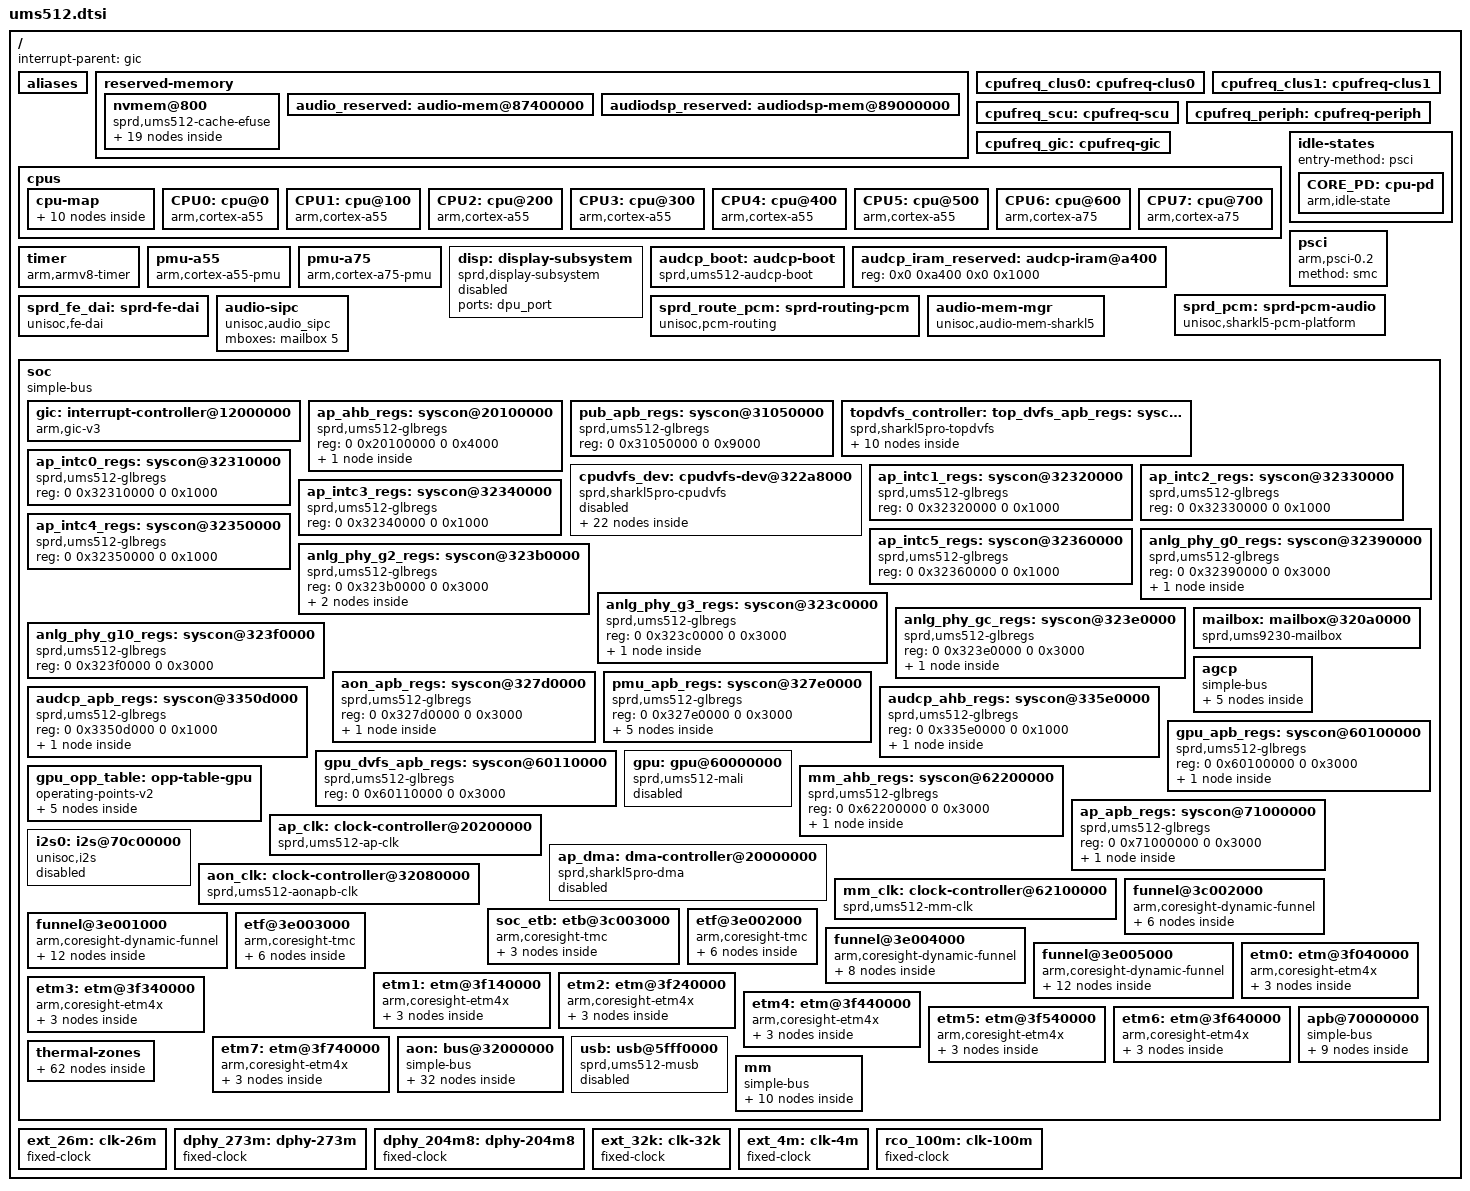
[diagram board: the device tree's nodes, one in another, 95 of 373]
// SPDX-License-Identifier: (GPL-2.0 OR MIT)
/*
 * Unisoc UMS512 SoC DTS file
 *
 * Copyright (C) 2021, Unisoc Inc.
 */

#include <dt-bindings/clock/sprd,ums512-clk.h>
#include <dt-bindings/reset/sprd,ums512-reset.h>
#include <dt-bindings/power/sprd,ums512-power.h>
#include <dt-bindings/interrupt-controller/arm-gic.h>
#include <dt-bindings/thermal/thermal.h>

/ {
	interrupt-parent = <&gic>;
	#address-cells = <2>;
	#size-cells = <2>;

	aliases {
		mmc0 = &sdio0;
		mmc3 = &sdio3;
		i2c0 = &i2c0;
		i2c1 = &i2c1;
		i2c2 = &i2c2;
		i2c3 = &i2c3;
		i2c4 = &i2c4;
	};

	reserved-memory {
		#address-cells = <2>;
		#size-cells = <2>;
		ranges;

		nvmem@800 {
			compatible = "sprd,ums512-cache-efuse", "nvmem-rmem";
			reg = <0 0x800 0 0x3ff>;
			no-map;

			nvmem-layout {
				compatible = "fixed-layout";
				#address-cells = <1>;
				#size-cells = <1>;

				thm0_sign: thm0-sign@38 {
					reg = <0x38 0x1>;
					bits = <0 1>;
				};

				thm0_ratio: thm0-ratio@38 {
					reg = <0x38 0x1>;
					bits = <1 7>;
				};

				thm0_sen0: thm0-sen0@39 {
					reg = <0x39 0x1>;
					bits = <0 8>;
				};

				thm0_sen1: thm0-sen1@41 {
					reg = <0x41 0x1>;
					bits = <0 8>;
				};

				thm0_sen2: thm0-sen2@40 {
					reg = <0x40 0x1>;
					bits = <0 8>;
				};

				thm0_sen3: thm0-sen3@43 {
					reg = <0x43 0x1>;
					bits = <0 8>;
				};

				thm0_sen4: thm0-sen4@42 {
					reg = <0x42 0x1>;
					bits = <0 8>;
				};

				thm1_sign: thm1-sign@3c {
					reg = <0x3c 0x1>;
					bits = <0 1>;
				};

				thm1_ratio: thm1-ratio@3c {
					reg = <0x3c 0x1>;
					bits = <1 7>;
				};

				thm1_sen0: thm1-sen0@3d {
					reg = <0x3d 0x1>;
					bits = <0 8>;
				};

				thm1_sen1: thm1-sen1@2f {
					reg = <0x2f 0x1>;
					bits = <0 8>;
				};

				thm1_sen2: thm1-sen2@2e {
					reg = <0x2e 0x1>;
					bits = <0 8>;
				};

				thm1_sen3: thm1-sen3@29 {
					reg = <0x29 0x1>;
					bits = <0 8>;
				};

				thm1_sen4: thm1-sen4@28 {
					reg = <0x28 0x1>;
					bits = <0 8>;
				};

				thm1_sen5: thm1-sen4@2b {
					reg = <0x2b 0x1>;
					bits = <0 8>;
				};

				thm2_sign: thm2-sign@3e {
					reg = <0x3e 0x1>;
					bits = <0 1>;
				};

				thm2_ratio: thm2-ratio@3e {
					reg = <0x3e 0x1>;
					bits = <1 7>;
				};

				thm2_sen0: thm2-sen0@3f {
					reg = <0x3f 0x1>;
					bits = <0 8>;
				};
			};
		};

		/* Stock audio carveouts (see device/stock/dtb_stock.dts) */
		audio_reserved: audio-mem@87400000 {
			reg = <0x0 0x87400000 0x0 0x400000>;
			no-map;
		};

		audiodsp_reserved: audiodsp-mem@89000000 {
			reg = <0x0 0x89000000 0x0 0x600000>;
			no-map;
		};
	};

	cpufreq_clus0: cpufreq-clus0 {
		cpufreq-cluster-id = <0>;
		cpufreq-sub-clusters = <&cpufreq_scu>,
				<&cpufreq_periph>,
				<&cpufreq_gic>;
		clock-latency = <50000>;
		voltage-tolerance = <6413>;
		sprd,multi-version;
		operating-points = <
		/* kHz     uV */
		1820000 1000000
		1716000 1000000
		1536000  900000
		1482000  900000
		1228800  800000
		1144000  800000
		962000   800000
		768000   800000
		614400   750000
		>;
	};

	cpufreq_clus1: cpufreq-clus1 {
		cpufreq-cluster-id = <1>;
		cpufreq-sub-clusters = <&cpufreq_scu>,
				<&cpufreq_periph>,
				<&cpufreq_gic>;
		clock-latency = <50000>;
		voltage-tolerance = <6413>;
		sprd,multi-version;
		operating-points = <
		/* kHz     uV */
		2002000 1000000
		1872000 1000000
		1742000 1000000
		1536000  900000
		1482000  800000
		1228800  750000
		>;
	};

	cpufreq_scu: cpufreq-scu {
		cpufreq-cluster-id = <2>;
		clock-latency = <50000>;
		voltage-tolerance = <0>;
		sprd,multi-version;
		operating-points = <
		/* kHz     uV */
		1404000 1000000
		1326000 1000000
		1222000  900000
		1118000  900000
		1014000  800000
		962000   800000
		768000   800000
		650000   800000
		546000   750000
		>;
	};

	cpufreq_periph: cpufreq-periph {
		cpufreq-cluster-id = <3>;
		clock-latency = <50000>;
		voltage-tolerance = <0>;
		sprd,multi-version;
		operating-points = <
		/* kHz    uV */
		768000 1000000
		512000  800000
		384000  800000
		256000  800000
		153600  750000
		>;
	};

	cpufreq_gic: cpufreq-gic {
		cpufreq-cluster-id = <4>;
		clock-latency = <50000>;
		voltage-tolerance = <0>;
		sprd,multi-version;
		operating-points = <
		/* kHz    uV */
		512000 800000
		384000 800000
		256000 800000
		192000 800000
		153600 750000
		>;
	};

	cpus {
		#address-cells = <2>;
		#size-cells = <0>;

		cpu-map {
			cluster0 {
				core0 {
					cpu = <&CPU0>;
				};
				core1 {
					cpu = <&CPU1>;
				};
				core2 {
					cpu = <&CPU2>;
				};
				core3 {
					cpu = <&CPU3>;
				};
				core4 {
					cpu = <&CPU4>;
				};
				core5 {
					cpu = <&CPU5>;
				};
			};
			cluster1 {
				core0 {
					cpu = <&CPU6>;
				};
				core1 {
					cpu = <&CPU7>;
				};
			};
		};

		CPU0: cpu@0 {
			device_type = "cpu";
			compatible = "arm,cortex-a55";
			reg = <0x0 0x0>;
			cpufreq-data-v1 = <&cpufreq_clus0>;
			enable-method = "psci";
			cpu-idle-states = <&CORE_PD>;
			clock-frequency = <1820000000>;
			capacity-dmips-mhz = <544>;
			dynamic-power-coefficient = <102>;
			#cooling-cells = <2>;
		};

		CPU1: cpu@100 {
			device_type = "cpu";
			compatible = "arm,cortex-a55";
			reg = <0x0 0x100>;
			cpufreq-data-v1 = <&cpufreq_clus0>;
			enable-method = "psci";
			cpu-idle-states = <&CORE_PD>;
			clock-frequency = <1820000000>;
			capacity-dmips-mhz = <544>;
			dynamic-power-coefficient = <102>;
			#cooling-cells = <2>;
		};

		CPU2: cpu@200 {
			device_type = "cpu";
			compatible = "arm,cortex-a55";
			reg = <0x0 0x200>;
			cpufreq-data-v1 = <&cpufreq_clus0>;
			enable-method = "psci";
			cpu-idle-states = <&CORE_PD>;
			clock-frequency = <1820000000>;
			capacity-dmips-mhz = <544>;
			dynamic-power-coefficient = <102>;
			#cooling-cells = <2>;
		};

		CPU3: cpu@300 {
			device_type = "cpu";
			compatible = "arm,cortex-a55";
			reg = <0x0 0x300>;
			cpufreq-data-v1 = <&cpufreq_clus0>;
			enable-method = "psci";
			cpu-idle-states = <&CORE_PD>;
			clock-frequency = <1820000000>;
			capacity-dmips-mhz = <544>;
			dynamic-power-coefficient = <102>;
			#cooling-cells = <2>;
		};

		CPU4: cpu@400 {
			device_type = "cpu";
			compatible = "arm,cortex-a55";
			reg = <0x0 0x400>;
			cpufreq-data-v1 = <&cpufreq_clus0>;
			enable-method = "psci";
			cpu-idle-states = <&CORE_PD>;
			clock-frequency = <1820000000>;
			capacity-dmips-mhz = <544>;
			dynamic-power-coefficient = <102>;
			#cooling-cells = <2>;
		};

		CPU5: cpu@500 {
			device_type = "cpu";
			compatible = "arm,cortex-a55";
			reg = <0x0 0x500>;
			cpufreq-data-v1 = <&cpufreq_clus0>;
			enable-method = "psci";
			cpu-idle-states = <&CORE_PD>;
			clock-frequency = <1820000000>;
			capacity-dmips-mhz = <544>;
			dynamic-power-coefficient = <102>;
			#cooling-cells = <2>;
		};

		CPU6: cpu@600 {
			device_type = "cpu";
			compatible = "arm,cortex-a75";
			reg = <0x0 0x600>;
			cpufreq-data-v1 = <&cpufreq_clus1>;
			enable-method = "psci";
			cpu-idle-states = <&CORE_PD>;
			clock-frequency = <1820000000>;
			capacity-dmips-mhz = <1024>;
			dynamic-power-coefficient = <501>;
			#cooling-cells = <2>;
		};

		CPU7: cpu@700 {
			device_type = "cpu";
			compatible = "arm,cortex-a75";
			reg = <0x0 0x700>;
			cpufreq-data-v1 = <&cpufreq_clus1>;
			enable-method = "psci";
			cpu-idle-states = <&CORE_PD>;
			clock-frequency = <1820000000>;
			capacity-dmips-mhz = <1024>;
			dynamic-power-coefficient = <501>;
			#cooling-cells = <2>;
		};
	};

	idle-states {
		entry-method = "psci";
		CORE_PD: cpu-pd {
			compatible = "arm,idle-state";
			entry-latency-us = <4000>;
			exit-latency-us = <4000>;
			min-residency-us = <10000>;
			local-timer-stop;
			arm,psci-suspend-param = <0x00010000>;
		};
	};

	psci {
		compatible = "arm,psci-0.2";
		method = "smc";
	};

	timer {
		compatible = "arm,armv8-timer";
		interrupts = <GIC_PPI 13 IRQ_TYPE_LEVEL_HIGH>, /* Physical Secure PPI */
			     <GIC_PPI 14 IRQ_TYPE_LEVEL_HIGH>, /* Physical Non-Secure PPI */
			     <GIC_PPI 11 IRQ_TYPE_LEVEL_HIGH>, /* Virtual PPI */
			     <GIC_PPI 10 IRQ_TYPE_LEVEL_HIGH>; /* Hipervisor PPI */
	};

	pmu-a55 {
		compatible = "arm,cortex-a55-pmu";
		interrupts = <GIC_SPI 112 IRQ_TYPE_LEVEL_HIGH>,
			     <GIC_SPI 113 IRQ_TYPE_LEVEL_HIGH>,
			     <GIC_SPI 114 IRQ_TYPE_LEVEL_HIGH>,
			     <GIC_SPI 115 IRQ_TYPE_LEVEL_HIGH>,
			     <GIC_SPI 116 IRQ_TYPE_LEVEL_HIGH>,
			     <GIC_SPI 117 IRQ_TYPE_LEVEL_HIGH>;
		interrupt-affinity = <&CPU0>, <&CPU1>, <&CPU2>, <&CPU3>, <&CPU4>, <&CPU5>;
	};

	pmu-a75 {
		compatible = "arm,cortex-a75-pmu";
		interrupts = <GIC_SPI 118 IRQ_TYPE_LEVEL_HIGH>,
			     <GIC_SPI 119 IRQ_TYPE_LEVEL_HIGH>;
		interrupt-affinity = <&CPU6>, <&CPU7>;
	};

	disp: display-subsystem {
		compatible = "sprd,display-subsystem";
		ports = <&dpu_port>;
		status = "disabled";
	};


	audcp_boot: audcp-boot {
		compatible = "sprd,ums512-audcp-boot";
		/*
		 * Stock omits dsp-reboot-mode (= mode 0, "dsp reboot by
		 * DDR"): the boot vector MUST be written, since we cold-load
		 * the firmware into DDR ourselves. Mode 1 skips the vector
		 * write and the DSP never executes the image.
		 */
		dsp-reboot-mode = <0>;
		sysshutdown = <&pmu_apb_regs 0x0060 0x02000000>;
		coreshutdown = <&pmu_apb_regs 0x005c 0x01000000>;
		deepsleep = <&pmu_apb_regs 0x00cc 0x00080000>;
		corereset = <&pmu_apb_regs 0x00b0 0x00000400>;
		sysreset = <&pmu_apb_regs 0x00b0 0x00000200>;
		reset_sel = <&pmu_apb_regs 0x07a4 0x000000ff>;
		sysstatus = <&pmu_apb_regs 0x00b8 0xff000000>;
		corestatus = <&pmu_apb_regs 0x010c 0x000000ff>;
		sleepstatus = <&pmu_apb_regs 0x00d4 0x0000f000>;
		bootprotect = <&aon_apb_regs 0x0078 0x0000ffff>;
		bootvector = <&aon_apb_regs 0x0140 0xffffffff>;
		bootaddress_sel = <&aon_apb_regs 0x0144 0x00000001>;
		accessenable = <&aon_apb_regs 0x014c 0x00000020>;
		memory-region = <&audiodsp_reserved>, <&audio_reserved>;
		sprd,audcp-aon-iram = <&audcp_iram_reserved>;
		#power-domain-cells = <0>;
		status = "okay";
	};

	/* AON IRAM window shared with the audio DSP (stock audcp-iram@a400) */
	audcp_iram_reserved: audcp-iram@a400 {
		reg = <0x0 0xa400 0x0 0x1000>;
	};

	sprd_pcm: sprd-pcm-audio {
		compatible = "unisoc,sharkl5-pcm-platform",
			     "unisoc,sharkl5pro-pcm-platform";
		#sound-dai-cells = <0>;
		/* agcp dma_ap */
		dmas = <&agcp_dma 1 &agcp_dma 2
			&agcp_dma 3 &agcp_dma 4
			&agcp_dma 17 &agcp_dma 18
			&agcp_dma 15 &agcp_dma 16
			&agcp_dma 14 &agcp_dma 8
			&agcp_dma 12 &agcp_dma 9
			&agcp_dma 13 &agcp_dma 8
			&agcp_dma 11 &agcp_dma 6
			&agcp_dma 14 &agcp_dma 14
			&agcp_dma 12 &agcp_dma 6
			&agcp_dma 7 &agcp_dma 20>;
		dma-names =
			"normal_p_l", "normal_p_r",
			"normal_c_l", "normal_c_r",
			"normal23_p_l", "normal23_p_r",
			"normal23_c_l", "normal23_c_r",
			"dspcap_c", "a2dppcm_p",
			"voice_c", "fast_p",
			"loop_c", "loop_p",
			"voip_c", "voip_p",
			"dspfmcap_c", "dspbtscocap_c",
			"recognise_c", "voice_pcm_p",
			"hifi_p", "hifi_fast_p";
	};

	sprd_fe_dai: sprd-fe-dai {
		compatible = "unisoc,fe-dai";
		#sound-dai-cells = <1>;
	};

	sprd_route_pcm: sprd-routing-pcm {
		compatible = "unisoc,pcm-routing";
		#sound-dai-cells = <0>;
	};

	audio-sipc {
		compatible = "unisoc,audio_sipc";
		mboxes = <&mailbox 5>;
	};

	audio-mem-mgr {
		compatible = "unisoc,audio-mem-sharkl5",
			     "unisoc,audio-mem-sharkl5pro";
		memory-region = <&audio_reserved>, <&audiodsp_reserved>;
		ddr32-ap-dsp-map-offset = <0x0>;
		/* 3M dynamic DMA alloc, 0x87400000 - 0x87700000 */
		sprd,ddr32-dma = <0x87400000 0x300000>;
		/* 512K DSP memdump, 0x87700000 - 0x87780000 */
		sprd,ddr32-dspmemdump = <0x87700000 0x80000>;
		/* 1K cmd para, 0x87780000 - 0x87780400 */
		sprd,cmdaddr = <0x87780000 0x400>;
		/* 2K + 16 bytes, 0x87780400 - 0x87780e10 */
		sprd,smsg-addr = <0x87780400 0xa10>;
		/* 1K AUDIO_STRUCT_PARA, 0x87780e10 - 0x87781210 */
		sprd,shmaddr-aud-str = <0x87780e10 0x400>;
		/* 5K DSP_VBC_PARA, 0x87781210 - 0x87782610 */
		sprd,shmaddr-dsp-vbc = <0x87781210 0x1400>;
		/* 1K nxp/cvs para, 0x87782610 - 0x87782a10 */
		sprd,shmaddr-nxp = <0x87782610 0x400>;
		/* 4K ivsence smartpa param, 0x87782a10 - 0x87783a10 */
		sprd,shmaddr-dsp-smartpa = <0x87782a10 0x1000>;
		/* 1K reg dump, 0x87783a10 - 0x87783e10 */
		sprd,shmaddr-reg-dump = <0x87783a10 0x400>;
		/* iram layout, total 32K */
		sprd,iram-ap-base = <0x33800000>;
		sprd,iram-dsp-base = <0x1800000>;
		sprd,offload-addr = <0x33800000 0x5c00>;
		sprd,normal-captue-linklilst-node1 = <0x33805e00 0x200>;
		sprd,normal-captue-data = <0x33806000 0x1e00>;
		sprd,normal-captue-linklilst-node2 = <0x33807e00 0x200>;
		sprd,audcp-aon-iram = <&audcp_iram_reserved>;
	};

	soc: soc {
		compatible = "simple-bus";
		#address-cells = <2>;
		#size-cells = <2>;
		ranges;

		gic: interrupt-controller@12000000 {
			compatible = "arm,gic-v3";
			reg = <0x0 0x12000000 0 0x20000>,	/* GICD */
			      <0x0 0x12040000 0 0x100000>;	/* GICR */
			#interrupt-cells = <3>;
			#address-cells = <2>;
			#size-cells = <2>;
			ranges;
			redistributor-stride = <0x0 0x20000>;	/* 128KB stride */
			#redistributor-regions = <1>;
			interrupt-controller;
			interrupts = <GIC_PPI 9 IRQ_TYPE_LEVEL_HIGH>;
		};

		ap_ahb_regs: syscon@20100000 {
			compatible = "sprd,ums512-glbregs", "syscon",
				     "simple-mfd";
			reg = <0 0x20100000 0 0x4000>;
			#address-cells = <1>;
			#size-cells = <1>;
			ranges = <0 0 0x20100000 0x4000>;

			apahb_gate: clock-controller@0 {
				compatible = "sprd,ums512-apahb-gate";
				reg = <0x0 0x3000>;
				clocks = <&ext_26m>;
				clock-names = "ext-26m";
				#clock-cells = <1>;
			};
		};

		pub_apb_regs: syscon@31050000 {
			compatible = "sprd,ums512-glbregs", "syscon",
				     "simple-mfd";
			reg = <0 0x31050000 0 0x9000>;
		};

		topdvfs_controller: top_dvfs_apb_regs: syscon@322a0000 {
			compatible = "sprd,sharkl5pro-topdvfs",
				     "sprd,ums512-glbregs", "syscon";
			reg = <0 0x322a0000 0 0x8000>;
			sprd,syscon-enable = <&aon_apb_regs>;
			module-enable-cfg = <0x4 7>;
			cpu-dcdc-cells = <&dcdc_cpu0>, <&dcdc_cpu1>;
			device-dcdc-cells = <&dcdc_mm>, <&dcdc_modem>;

			dcdc_cpu0: dcdc-cpu0 {
				dcdc-dvfs-enable = <0x68 20 1>;
				dcdc-judge-vol-sw = <0x68 1 0x7 0>;
				dcdc-subsys-tune-enable = <0x150 6 1>;
				dcdc-idle-voltage = <0x16c 3 0x7 6>;
			};

			dcdc_cpu1: dcdc-cpu1 {
				dcdc-dvfs-enable = <0x94 0 1>;
				dcdc-judge-vol-sw = <0x138 15 0x7 0>;
				dcdc-subsys-tune-enable = <0x150 7 1>;
				dcdc-idle-voltage = <0x16c 0 0x7 5>;
			};

			dcdc_mm: dcdc-mm {
				dcdc-dvfs-enable = <0x18 20 1>;
				dcdc-judge-vol-sw = <0x18 1 0x7 2>;
				dcdc-subsys-cells = <&audcp_sys>,
						<&gpu_sys>,
						<&mm_sys>;
				audcp_sys: audcp-sys {
					dcdc-subsys-tune-enable = <0x150 5 1>;
				};
				gpu_sys: gpu-sys {
					dcdc-subsys-tune-enable = <0x150 1 1>;
				};
				mm_sys: mm-sys {
					dcdc-subsys-tune-enable = <0x150 2 1>;
				};
			};

			dcdc_modem: dcdc-modem {
				dcdc-dvfs-enable = <0x3c 20 1>;
				dcdc-judge-vol-sw = <0x3c 1 0x7 2>;
				dcdc-subsys-cells = <&pubcp_sys>,
						<&wtlcp_sys>,
						<&ap_sys>;
				pubcp_sys: pubcp-sys {
					dcdc-subsys-tune-enable = <0x150 4 0>;
				};
				wtlcp_sys: wtlcp-sys {
					dcdc-subsys-tune-enable = <0x150 3 0>;
				};
				ap_sys: ap-sys {
					dcdc-subsys-tune-enable = <0x150 0 1>;
				};
			};
		};

		cpudvfs_dev: cpudvfs-dev@322a8000 {
			compatible = "sprd,sharkl5pro-cpudvfs";
			reg = <0 0x322a8000 0 0x1000>;
			sprd,syscon-enable = <&aon_apb_regs>;
			module-enable-cfg = <0x4 7>;
			topdvfs-controller = <&topdvfs_controller>;
			mpll-cells = <&mpll_0>, <&mpll_1>, <&mpll_2>;
			apcpu-dvfs-dcdc-cells = <&apcpu_cpu0>, <&apcpu_cpu1>;
			cpudvfs-clusters = <&lit_core_cluster>,
					<&big_core_cluster>,
					<&scu_cluster>,
					<&periph_cluster>,
					<&gic_cluster>;
			status = "disabled";

			lit_core_cluster: lit-core-cluster {
				cluster-name = "lit-core-cluster";
				row-num = <11>;
				column-num = <7>;
				work-index-cfg = <0x214 0xf>;
				idle-index-cfg = <0x218 0xf>;
				tuning-result-judge = <0>;
				dcdc-name = "DCDC_CPU0";
				map-tbl-regs = <0x60 0x64 0x68 0x6c 0x70 0x74 0x78 0x7c 0x80 0x84 0x88>;
				column-entry-start-bit = <0 2 15 5 9 18 12>;
				column-entry-mask = <0x3 0x7 0x7 0xf 0x7 0x7 0x7>;
				cluster-devices = <&lit_core0_dev>,
						<&lit_core1_dev>,
						<&lit_core2_dev>,
						<&lit_core3_dev>,
						<&lit_core4_dev>,
						<&lit_core5_dev>;
				/* sel, div, vol, vote_scu, vote_peri, vote_gic, mpllx */
				lit-core-dvfs-tbl = <
						0 0 0 0 0 0 0
						1 1 0 1 1 1 0
						2 1 1 2 2 2 0
						3 0 1 3 2 3 0
						3 0 1 4 3 4 1
						1 0 1 5 4 4 0
						3 0 2 6 4 4 2
						2 0 2 7 4 4 0
						3 0 3 8 4 5 3
						3 0 3 9 5 5 4
						3 0 3 9 5 5 4
					>;
				lit_core0_dev: lit-core0-dev {
					device-name = "cpu0";
					sel-get = <0x38 0 3>;
					div-get = <0x38 2 7>;
					vol-get = <0x30 0 7>;
					dfs-idle-disable = <0x1c 0 1>;
				};
				lit_core1_dev: lit-core1-dev {
					device-name = "cpu1";
					sel-get = <0x38 5 3>;
					div-get = <0x38 7 7>;
					vol-get = <0x30 3 7>;
					dfs-idle-disable = <0x1c 1 1>;
				};
				lit_core2_dev: lit-core2-dev {
					device-name = "cpu2";
					sel-get = <0x38 10 3>;
					div-get = <0x38 12 7>;
					vol-get = <0x30 6 7>;
					dfs-idle-disable = <0x1c 2 1>;
				};
				lit_core3_dev: lit-core3-dev {
					device-name = "cpu3";
					sel-get = <0x38 15 3>;
					div-get = <0x38 17 7>;
					vol-get = <0x30 9 7>;
					dfs-idle-disable = <0x1c 3 1>;
				};
				lit_core4_dev: lit-core4-dev {
					device-name = "cpu4";
					sel-get = <0x40 0 3>;
					div-get = <0x40 2 7>;
					vol-get = <0x34 0 7>;
					dfs-idle-disable = <0x1c 8 1>;
				};
				lit_core5_dev: lit-core5-dev {
					device-name = "cpu5";
					sel-get = <0x40 5 3>;
					div-get = <0x40 7 7>;
					vol-get = <0x34 3 7>;
					dfs-idle-disable = <0x1c 9 1>;
				};
			};

			big_core_cluster: big-core-cluster {
				cluster-name = "big-core-cluster";
				row-num = <7>;
				column-num = <7>;
				work-index-cfg = <0x224 0xf>;
				idle-index-cfg = <0x228 0xf>;
				tuning-result-judge = <0>;
				dcdc-name = "DCDC_CPU1";
				map-tbl-regs = <0xa0 0xa4 0xa8 0xac 0xb0 0xb4 0xb8>;
				column-entry-start-bit = <0 2 15 5 9 21 12>;
				column-entry-mask = <0x3 0x7 0x7 0xf 0x7 0x7 0x7>;
				cluster-devices = <&big_core0_dev>,
						<&big_core1_dev>;
				/* sel, div, vol, vote_scu, vote_peri, vote_gic, mpllx */
				big-core-dvfs-tbl = <
						0 0 0 0 0 0 0
						1 0 0 3 3 4 0
						3 0 1 5 4 4 0
						2 0 2 6 4 4 0
						3 0 3 7 4 5 1
						3 0 3 8 4 5 3
						3 0 3 9 5 5 4
					>;
				big_core0_dev: big-core0-dev {
					device-name = "cpu6";
					sel-get = <0x40 10 3>;
					div-get = <0x40 12 7>;
					vol-get = <0x34 6 7>;
					dfs-idle-disable = <0x1c 10 1>;
				};
				big_core1_dev: big-core1-dev {
					device-name = "cpu7";
					sel-get = <0x40 15 3>;
					div-get = <0x40 17 7>;
					vol-get = <0x34 9 7>;
					dfs-idle-disable = <0x1c 11 1>;
				};
			};

			scu_cluster: scu-cluster {
				cluster-name = "scu-cluster";
				row-num = <10>;
				column-num = <5>;
				work-index-cfg = <0x22C 0xf>;
				idle-index-cfg = <0x230 0xf>;
				dcdc-name = "DCDC_CPU0";
				tuning-func-cfg = <0x18 1>;
				map-tbl-regs = <0x180 0x184 0x188 0x18c 0x190 0x194 0x198 0x19c 0x1a0 0x1a4>;
				column-entry-start-bit = <0 2 11 5 8>;
				column-entry-mask = <0x3 0x7 0x7 0x7 0x7>;
				cluster-devices = <&scu_dev>, <&ace_dev>;
				/* sel div vol ace_div mpllx */
				scu-dvfs-tbl = <
					0 0 0 0 0
					3 0 0 1 0
					3 0 1 1 1
					1 0 1 1 0
					3 0 1 1 2
					3 0 1 1 3
					3 0 2 1 4
					3 0 3 1 5
					3 0 3 1 6
					3 0 3 1 7
				>;
				scu_dev: scu-dev {
					device-name = "scu";
					sel-get = <0x38 20 3>;
					div-get = <0x38 22 7>;
					vol-get = <0x30 12 7>;
					dfs-idle-disable = <0x1c 4 1>;
				};
				ace_dev: ace-dev {
					device-name = "ace";
					sel-get = <0x38 20 3>;
					div-get = <0x38 25 7>;
					vol-get = <0x30 12 7>;
				};
			};

			periph_cluster: periph-cluster {
				cluster-name = "periph-cluster";
				row-num = <6>;
				column-num = <3>;
				work-index-cfg = <0x23C 0x7>;
				idle-index-cfg = <0x240 0x7>;
				dcdc-name = "DCDC_CPU0";
				tuning-func-cfg = <0x18 0>;
				map-tbl-regs = <0x1f4 0x1f8 0x1fc 0x200 0x204 0x208>;
				column-entry-start-bit = <0 2 5>;
				column-entry-mask = <0x3 0x7 0x7>;
				cluster-devices = <&periph_dev>;
				/* sel div vol */
				periph-dvfs-tbl = <
					0 0 0
					1 0 0
					2 1 1
					3 1 1
					2 0 1
					3 0 3
				>;
				periph_dev: periph-dev {
					device-name = "periph";
					sel-get = <0x3C 0 3>;
					div-get = <0x3C 2 7>;
					vol-get = <0x30 18 7>;
					dfs-idle-disable = <0x1c 6 1>;
				};
			};

			gic_cluster: gic-cluster {
				cluster-name = "gic-cluster";
				row-num = <6>;
				column-num = <3>;
				work-index-cfg = <0x2e0 0x7>;
				idle-index-cfg = <0x2e4 0x7>;
				dcdc-name = "DCDC_CPU0";
				tuning-func-cfg = <0x18 2>;
				map-tbl-regs = <0x280 0x284 0x288 0x28c 0x290 0x294>;
				column-entry-start-bit = <0 2 5>;
				column-entry-mask = <0x3 0x7 0x7>;
				cluster-devices = <&gic_dev>;
				/* sel div vol */
				gic-dvfs-tbl = <
					0 0 0
					1 0 0
					2 1 1
					3 1 1
					2 0 1
					3 0 1
				>;
				gic_dev: gic-dev {
					device-name = "gic";
					sel-get = <0x3c 12 3>;
					div-get = <0x3c 14 7>;
					vol-get = <0x30 21 7>;
					dfs-idle-disable = <0x1c 7 1>;
				};
			};

			mpll_0: mpll-ananke {
				sprd,syscon-ang = <&anlg_phy_g3_regs>;
				mpll-rst = <0x98 4 6 7>;
				relock-cfg = <0x244 1>;
				pd-cfg = <0x244 0>;
			};
			mpll_1: mpll-prometheus {
				sprd,syscon-ang = <&anlg_phy_g2_regs>;
				mpll-rst = <0x44 4 6 7>;
				relock-cfg = <0x258 1>;
				pd-cfg = <0x258 0>;
			};
			mpll_2: mpll-scu {
				sprd,syscon-ang = <&anlg_phy_g3_regs>;
				mpll-rst = <0xdc 3 5 6>;
				relock-cfg = <0x26c 1>;
				pd-cfg = <0x26c 0>;
			};

			apcpu_cpu0: apcpu-cpu0 {
				subsys-dcdc-vol-sw = <0x20 4 0x7 6>;
				subsys-dvfs-state = <0x44 0 7>;
			};
			apcpu_cpu1: apcpu-cpu1 {
				subsys-dcdc-vol-sw = <0x24 4 0x7 5>;
				subsys-dvfs-state = <0x4c 0 7>;
			};
		};

		ap_intc0_regs: syscon@32310000 {
			compatible = "sprd,ums512-glbregs", "syscon",
				     "simple-mfd";
			reg = <0 0x32310000 0 0x1000>;
		};

		ap_intc1_regs: syscon@32320000 {
			compatible = "sprd,ums512-glbregs", "syscon",
				     "simple-mfd";
			reg = <0 0x32320000 0 0x1000>;
		};

		ap_intc2_regs: syscon@32330000 {
			compatible = "sprd,ums512-glbregs", "syscon",
				     "simple-mfd";
			reg = <0 0x32330000 0 0x1000>;
		};

		ap_intc3_regs: syscon@32340000 {
			compatible = "sprd,ums512-glbregs", "syscon",
				     "simple-mfd";
			reg = <0 0x32340000 0 0x1000>;
		};

		ap_intc4_regs: syscon@32350000 {
			compatible = "sprd,ums512-glbregs", "syscon",
				     "simple-mfd";
			reg = <0 0x32350000 0 0x1000>;
		};

		ap_intc5_regs: syscon@32360000 {
			compatible = "sprd,ums512-glbregs", "syscon",
				     "simple-mfd";
			reg = <0 0x32360000 0 0x1000>;
		};

		anlg_phy_g0_regs: syscon@32390000 {
			compatible = "sprd,ums512-glbregs", "syscon",
				     "simple-mfd";
			reg = <0 0x32390000 0 0x3000>;
			#address-cells = <1>;
			#size-cells = <1>;
			ranges = <0 0 0x32390000 0x3000>;

			dpll0: clock-controller@0 {
				compatible = "sprd,ums512-g0-pll";
				reg = <0x0 0x100>;
				#clock-cells = <1>;
			};
		};

		anlg_phy_g2_regs: syscon@323b0000 {
			compatible = "sprd,ums512-glbregs", "syscon",
				     "simple-mfd";
			reg = <0 0x323b0000 0 0x3000>;
			#address-cells = <1>;
			#size-cells = <1>;
			ranges = <0 0 0x323b0000 0x3000>;

			mpll1: clock-controller@0 {
				compatible = "sprd,ums512-g2-pll";
				reg = <0x0 0x100>;
				#clock-cells = <1>;
			};

			hsphy: phy@100 {
				compatible = "sprd,ums512-hsphy";
				reg = <0x100 0x2000>;
				sprd,syscon-aon-apb = <&aon_apb_regs>;
				#phy-cells = <0>;
				status = "disabled";
			};
		};

		anlg_phy_g3_regs: syscon@323c0000 {
			compatible = "sprd,ums512-glbregs", "syscon",
				     "simple-mfd";
			reg = <0 0x323c0000 0 0x3000>;
			#address-cells = <1>;
			#size-cells = <1>;
			ranges = <0 0 0x323c0000 0x3000>;

			pll1: clock-controller@0 {
				compatible = "sprd,ums512-g3-pll";
				reg = <0x0 0x3000>;
				clocks = <&ext_26m>;
				clock-names = "ext-26m";
				#clock-cells = <1>;
			};
		};

		anlg_phy_gc_regs: syscon@323e0000 {
			compatible = "sprd,ums512-glbregs", "syscon",
				     "simple-mfd";
			reg = <0 0x323e0000 0 0x3000>;
			#address-cells = <1>;
			#size-cells = <1>;
			ranges = <0 0 0x323e0000 0x3000>;

			pll2: clock-controller@0 {
				compatible = "sprd,ums512-gc-pll";
				reg = <0x0 0x100>;
				clocks = <&ext_26m>;
				clock-names = "ext-26m";
				#clock-cells = <1>;
			};
		};

		anlg_phy_g10_regs: syscon@323f0000 {
			compatible = "sprd,ums512-glbregs", "syscon",
				     "simple-mfd";
			reg = <0 0x323f0000 0 0x3000>;
		};

		aon_apb_regs: syscon@327d0000 {
			compatible = "sprd,ums512-glbregs", "syscon",
				     "simple-mfd";
			reg = <0 0x327d0000 0 0x3000>;
			#address-cells = <1>;
			#size-cells = <1>;
			ranges = <0 0 0x327d0000 0x3000>;

			aonapb_gate: clock-controller@0 {
				compatible = "sprd,ums512-aon-gate";
				reg = <0x0 0x3000>;
				clocks = <&ext_26m>;
				clock-names = "ext-26m";
				#clock-cells = <1>;
			};
		};

		pmu_apb_regs: syscon@327e0000 {
			compatible = "sprd,ums512-glbregs", "syscon",
				     "simple-mfd";
			reg = <0 0x327e0000 0 0x3000>;
			#address-cells = <1>;
			#size-cells = <1>;
			ranges = <0 0 0x327e0000 0x3000>;

			pmu_gate: clock-controller@0 {
				compatible = "sprd,ums512-pmu-gate";
				reg = <0x0 0x3000>;
				clocks = <&ext_26m>;
				clock-names = "ext-26m";
				#clock-cells = <1>;
				#reset-cells = <1>;
			};

			pmu: power-controller {
				compatible = "sprd,ums512-power-controller";
				#address-cells = <1>;
				#size-cells = <0>;
				#power-domain-cells = <1>;

				power-domain@UMS512_POWER_DOMAIN_GPU_TOP {
					reg = <UMS512_POWER_DOMAIN_GPU_TOP>;
					clocks = <&aonapb_gate CLK_GPU_EB>;
					#power-domain-cells = <0>;
				};

				power-domain@UMS512_POWER_DOMAIN_MM {
					reg = <UMS512_POWER_DOMAIN_MM>;
					clocks = <&aonapb_gate CLK_MM_EB>;
					#power-domain-cells = <0>;
				};

				power-domain@UMS512_POWER_DOMAIN_PUBCP {
					reg = <UMS512_POWER_DOMAIN_PUBCP>;
					#power-domain-cells = <0>;
				};
			};
		};

		audcp_apb_regs: syscon@3350d000 {
			compatible = "sprd,ums512-glbregs", "syscon",
				     "simple-mfd";
			reg = <0 0x3350d000 0 0x1000>;
			#address-cells = <1>;
			#size-cells = <1>;
			ranges = <0 0 0x3350d000 0x1000>;

			audcpapb_gate: clock-controller@0 {
				compatible = "sprd,ums512-audcpapb-gate";
				reg = <0x0 0x300>;
				#clock-cells = <1>;
			};
		};

		audcp_ahb_regs: syscon@335e0000 {
			compatible = "sprd,ums512-glbregs", "syscon",
				     "simple-mfd";
			reg = <0 0x335e0000 0 0x1000>;
			#address-cells = <1>;
			#size-cells = <1>;
			ranges = <0 0 0x335e0000 0x1000>;

			audcpahb_gate: clock-controller@0 {
				compatible = "sprd,ums512-audcpahb-gate";
				reg = <0x0 0x300>;
				#clock-cells = <1>;
			};
		};

		mailbox: mailbox@320a0000 {
			compatible = "sprd,ums9230-mailbox";
			reg = <0x0 0x320a0000 0x0 0x8000>,
			      <0x0 0x320a8000 0x0 0x8000>;
			clocks = <&aonapb_gate CLK_MBOX_EB>;
			clock-names = "enable";
			interrupts = <GIC_SPI 82 IRQ_TYPE_LEVEL_HIGH>,
				     <GIC_SPI 83 IRQ_TYPE_LEVEL_HIGH>,
				     <GIC_SPI 84 IRQ_TYPE_LEVEL_HIGH>;
			interrupt-names = "inbox", "outbox", "supp-outbox";
			#mbox-cells = <1>;
			status = "okay";
		};

		agcp {
			compatible = "simple-bus";
			#address-cells = <2>;
			#size-cells = <2>;
			ranges;

			vbc_v4: vbc@33480000 {
				compatible = "unisoc,sharkl5-vbc",
					     "unisoc,sharkl5pro-vbc";
				#sound-dai-cells = <1>;
				reg = <0 0x33480000 0 0x1000>;
				sprd,syscon-agcp-ahb = <&audcp_ahb_regs>;
				sprd,vbc-phy-offset = <0x32000000>;
				power-domains = <&audcp_boot>;
				/* iis pin map */
				pinctrl-names =
				"vbc_iis3_0", "vbc_iism0_0",
				"vbc_iis_to_pad", "vbc_iis_to_aon_usb",
				"vbc_iism0_1", "vbc_iism0_3",
				"vbc_iis0_3", "vbc_iis1_3", "vbc_iis2_3",
				"vbc_iis3_3", "ap_iis0_3";
				pinctrl-0 = <&vbc_iis3_0>;
				pinctrl-1 = <&vbc_iism0_0>;
				pinctrl-2 = <&vbc_iis_to_pad>;
				pinctrl-3 = <&vbc_iis_to_aon_usb>;
				pinctrl-4 = <&vbc_iism0_1>;
				pinctrl-5 = <&vbc_iism0_3>;
				pinctrl-6 = <&vbc_iis0_3>;
				pinctrl-7 = <&vbc_iis1_3>;
				pinctrl-8 = <&vbc_iis2_3>;
				pinctrl-9 = <&vbc_iis3_3>;
				pinctrl-10 = <&ap_iis0_3>;
			};

			mcdt@33490000 {
				compatible = "unisoc,sharkl5-mcdt",
					     "unisoc,sharkl5pro-mcdt";
				reg = <0 0x33490000 0 0x170>;
				interrupts = <GIC_SPI 182 IRQ_TYPE_LEVEL_HIGH>;
				power-domains = <&audcp_boot>;
				sprd,ap-addr-offset = <0x32000000>;
				sprd,syscon-agcp-ahb = <&audcp_ahb_regs>;
			};

			agcp_dma: dma-controller@33580000 {
				compatible = "sprd,sharkl5pro-dma",
					     "sprd,sc9860-dma";
				reg = <0 0x33580000 0 0x4000>;
				interrupts = <GIC_SPI 180 IRQ_TYPE_LEVEL_HIGH>;
				power-domains = <&audcp_boot>;
				#dma-cells = <1>;
				dma-channels = <32>;
				clock-names = "enable", "ashb_eb";
				clocks = <&audcpahb_gate CLK_AUDCP_DMA_AP_EB>,
					 <&audcpahb_gate CLK_AUDCP_DMA_AP_ASHB_EB>;
			};

			sprd_audio_codec_dig: audio-codec@33750000 {
				compatible = "unisoc,audio-codec-dig-agcp";
				reg = <0 0x33750000 0 0x1000>;
				power-domains = <&audcp_boot>;
				sprd,syscon-agcp-ahb = <&audcp_ahb_regs>;
			};

			agdsp-access {
				compatible = "unisoc,agdsp-access";
				sprd,syscon-agcp-ahb = <&aon_apb_regs>;
				sprd,syscon-pmu-apb = <&pmu_apb_regs>;
				audcp_pmu_sleep_ctrl = <&pmu_apb_regs 0xcc 0x20>;
				audcp_pmu_slp_status = <&pmu_apb_regs 0xd4 0xf000>;
				audcp_pmu_pwr_status4 = <&pmu_apb_regs 0xb8 0xff000000>;
				audcp_pmu_pwr_status3 = <&pmu_apb_regs 0x10c 0xff>;
				ap_access_ena = <&aon_apb_regs 0x14c 0x20>;
				sprd,ddr-addr-offset = <0x0>;
				sprd,auto_agcp_access = <0>;
			};
		};

		gpu_apb_regs: syscon@60100000 {
			compatible = "sprd,ums512-glbregs", "syscon",
				     "simple-mfd";
			reg = <0 0x60100000 0 0x3000>;
			#address-cells = <1>;
			#size-cells = <1>;
			ranges = <0 0 0x60100000 0x3000>;

			gpu_clk: clock-controller@0 {
				compatible = "sprd,ums512-gpu-clk";
				clocks = <&ext_26m>;
				clock-names = "ext-26m";
				reg = <0x0 0x100>;
				power-domains = <&pmu UMS512_POWER_DOMAIN_GPU_TOP>;
				#clock-cells = <1>;
				#reset-cells = <1>;
			};
		};

		gpu_dvfs_apb_regs: syscon@60110000 {
			compatible = "sprd,ums512-glbregs", "syscon",
				     "simple-mfd";
			reg = <0 0x60110000 0 0x3000>;
		};

		gpu: gpu@60000000 {
			compatible = "sprd,ums512-mali", "arm,mali-bifrost";
			reg = <0 0x60000000 0 0x100000>;
			interrupts = <GIC_SPI 60 IRQ_TYPE_LEVEL_HIGH>,
				     <GIC_SPI 60 IRQ_TYPE_LEVEL_HIGH>,
				     <GIC_SPI 60 IRQ_TYPE_LEVEL_HIGH>;
			interrupt-names = "job", "mmu", "gpu";
			clocks = <&gpu_clk CLK_GPU_CORE_EB>,
				 <&gpu_clk CLK_GPU_MEM_EB>,
				 <&gpu_clk CLK_GPU_SYS_EB>;
			clock-names = "gpu", "mem", "bus";
			power-domains = <&pmu UMS512_POWER_DOMAIN_GPU_TOP>;
			resets = <&gpu_clk RESET_GPU_APB_SYS_SOFT_RST_REQ_CORE>;
			operating-points-v2 = <&gpu_opp_table>;

			status = "disabled";
		};

		gpu_opp_table: opp-table-gpu {
			compatible = "operating-points-v2";

			opp-384000000 {
				opp-hz = /bits/ 64 <384000000>;
				opp-microvolt = <700000>;
			};
			opp-512000000 {
				opp-hz = /bits/ 64 <512000000>;
				opp-microvolt = <750000>;
			};
			opp-614400000 {
				opp-hz = /bits/ 64 <614400000>;
				opp-microvolt = <750000>;
			};
			opp-768000000 {
				opp-hz = /bits/ 64 <768000000>;
				opp-microvolt = <800000>;
			};
			opp-850000000 {
				opp-hz = /bits/ 64 <850000000>;
				opp-microvolt = <800000>;
			};
		};

		mm_ahb_regs: syscon@62200000 {
			compatible = "sprd,ums512-glbregs", "syscon",
				     "simple-mfd";
			reg = <0 0x62200000 0 0x3000>;
			#address-cells = <1>;
			#size-cells = <1>;
			ranges = <0 0 0x62200000 0x3000>;

			mm_gate: clock-controller@0 {
				compatible = "sprd,ums512-mm-gate-clk";
				reg = <0x0 0x3000>;
				power-domains = <&pmu UMS512_POWER_DOMAIN_MM>;
				#clock-cells = <1>;
			};
		};

		ap_apb_regs: syscon@71000000 {
			compatible = "sprd,ums512-glbregs", "syscon",
				     "simple-mfd";
			reg = <0 0x71000000 0 0x3000>;
			#address-cells = <1>;
			#size-cells = <1>;
			ranges = <0 0 0x71000000 0x3000>;

			apapb_gate: clock-controller@0 {
				compatible = "sprd,ums512-apapb-gate";
				reg = <0x0 0x3000>;
				#clock-cells = <1>;
			};
		};

		ap_clk: clock-controller@20200000 {
			compatible = "sprd,ums512-ap-clk";
			reg = <0 0x20200000 0 0x1000>;
			clocks = <&ext_26m>;
			clock-names = "ext-26m";
			#clock-cells = <1>;
		};

		ap_dma: dma-controller@20000000 {
			/* AP-owned DMA (GIC_SPI 24) used by the i2s0 audio path;
			 * distinct from the audcp agcp_dma whose IRQ is dead.
			 */
			compatible = "sprd,sharkl5pro-dma", "sprd,sc9860-dma";
			reg = <0 0x20000000 0 0x4000>;
			interrupts = <GIC_SPI 24 IRQ_TYPE_LEVEL_HIGH>;
			#dma-cells = <1>;
			#dma-channels = <28>;
			clock-names = "enable";
			clocks = <&apahb_gate CLK_DMA_PUB_EB>;
			status = "disabled";
		};

		i2s0: i2s@70c00000 {
			/* binds the ported unisoc audio_driver i2s CPU-DAI */
			compatible = "unisoc,i2s";
			reg = <0 0x70c00000 0 0x1000>;
			sprd,dai_name = "i2s_bt_sco0";
			sprd,hw_port = <0>;
			sprd,syscon-ap-apb = <&ap_apb_regs>;
			#sound-dai-cells = <0>;
			clock-names = "clk_iis0",
				      "clk_twpll_128m",
				      "clk_twpll_153m6";
			clocks = <&ap_clk CLK_AP_IIS0>,
				 <&pll2 CLK_TWPLL_128M>,
				 <&pll2 CLK_TWPLL_153M6>;
			status = "disabled";
		};

		aon_clk: clock-controller@32080000 {
			compatible = "sprd,ums512-aonapb-clk";
			reg = <0 0x32080000 0 0x1000>;
			clocks = <&ext_26m>, <&ext_32k>,
				 <&ext_4m>, <&rco_100m>;
			clock-names = "ext-26m", "ext-32k",
				      "ext-4m", "rco-100m";
			#clock-cells = <1>;
		};

		mm_clk: clock-controller@62100000 {
			compatible = "sprd,ums512-mm-clk";
			reg = <0 0x62100000 0 0x1000>;
			/*
			 * The MM CKG register file needs MM_CKG_EB in addition
			 * to the MM power domain being on; without it any read
			 * of this block bus-faults (mirrors ums9230's mm_clk).
			 */
			clocks = <&ext_26m>, <&mm_gate CLK_MM_CKG_EB>;
			clock-names = "ext-26m", "enable";
			power-domains = <&pmu UMS512_POWER_DOMAIN_MM>;
			#clock-cells = <1>;
		};

		/* SoC Funnel */
		funnel@3c002000 {
			compatible = "arm,coresight-dynamic-funnel", "arm,primecell";
			reg = <0 0x3c002000 0 0x1000>;
			clocks = <&ext_26m>;
			clock-names = "apb_pclk";

			out-ports {
				port {
					funnel_soc_out_port: endpoint {
						remote-endpoint = <&etb_in>;
					};
				};
			};

			in-ports {
				#address-cells = <1>;
				#size-cells = <0>;

				port@1 {
					reg = <1>;
					funnel_soc_in_port: endpoint {
						remote-endpoint =
						<&funnel_corinth_out_port>;
					};
				};
			};
		};

		/* SoC ETF */
		soc_etb: etb@3c003000 {
			compatible = "arm,coresight-tmc", "arm,primecell";
			reg = <0 0x3c003000 0 0x1000>;
			clocks = <&ext_26m>;
			clock-names = "apb_pclk";

			in-ports {
				port {
					etb_in: endpoint {
						remote-endpoint =
						<&funnel_soc_out_port>;
					};
				};
			};
		};

		/* AP-CPU Funnel for core3/4/5/7 */
		funnel@3e001000 {
			compatible = "arm,coresight-dynamic-funnel", "arm,primecell";
			reg = <0 0x3e001000 0 0x1000>;
			clocks = <&ext_26m>;
			clock-names = "apb_pclk";

			out-ports {
				port {
					funnel_corinth_lit_out_port: endpoint {
						remote-endpoint =
						<&corinth_etf_lit_in>;
					};
				};
			};

			in-ports {
				#address-cells = <1>;
				#size-cells = <0>;

				port@0 {
					reg = <0>;
					funnel_core_in_port3: endpoint {
						remote-endpoint = <&etm3_out>;
					};
				};

				port@1 {
					reg = <1>;
					funnel_core_in_port4: endpoint {
						remote-endpoint = <&etm4_out>;
					};
				};

				port@2 {
					reg = <2>;
					funnel_core_in_port5: endpoint {
						remote-endpoint = <&etm5_out>;
					};
				};

				port@3 {
					reg = <3>;
					funnel_core_in_port7: endpoint {
						remote-endpoint = <&etm7_out>;
					};
				};
			};
		};

		/* AP-CPU ETF for little cores */
		etf@3e002000 {
			compatible = "arm,coresight-tmc", "arm,primecell";
			reg = <0 0x3e002000 0 0x1000>;
			clocks = <&ext_26m>;
			clock-names = "apb_pclk";

			out-ports {
				port {
					corinth_etf_lit_out: endpoint {
						remote-endpoint =
						<&funnel_corinth_from_lit_in_port>;
					};
				};
			};

			in-ports {
				port {
					corinth_etf_lit_in: endpoint {
						remote-endpoint =
						<&funnel_corinth_lit_out_port>;
					};
				};
			};
		};

		/* AP-CPU ETF for big cores */
		etf@3e003000 {
			compatible = "arm,coresight-tmc", "arm,primecell";
			reg = <0 0x3e003000 0 0x1000>;
			clocks = <&ext_26m>;
			clock-names = "apb_pclk";

			out-ports {
				port {
					corinth_etf_big_out: endpoint {
						remote-endpoint =
						<&funnel_corinth_from_big_in_port>;
					};
				};
			};

			in-ports {
				port {
					corinth_etf_big_in: endpoint {
						remote-endpoint =
						<&funnel_corinth_big_out_port>;
					};
				};
			};
		};

		/* Funnel to SoC */
		funnel@3e004000 {
			compatible = "arm,coresight-dynamic-funnel", "arm,primecell";
			reg = <0 0x3e004000 0 0x1000>;
			clocks = <&ext_26m>;
			clock-names = "apb_pclk";

			out-ports {
				port {
					funnel_corinth_out_port: endpoint {
						remote-endpoint =
						<&funnel_soc_in_port>;
					};
				};
			};

			in-ports {
				#address-cells = <1>;
				#size-cells = <0>;

				port@0 {
					reg = <0>;
					funnel_corinth_from_lit_in_port: endpoint {
						remote-endpoint = <&corinth_etf_lit_out>;
					};
				};

				port@1 {
					reg = <1>;
					funnel_corinth_from_big_in_port: endpoint {
						remote-endpoint = <&corinth_etf_big_out>;
					};
				};
			};
		};

		/* AP-CPU Funnel for core0/1/2/6 */
		funnel@3e005000 {
			compatible = "arm,coresight-dynamic-funnel", "arm,primecell";
			reg = <0 0x3e005000 0 0x1000>;
			clocks = <&ext_26m>;
			clock-names = "apb_pclk";

			out-ports {
				port {
					funnel_corinth_big_out_port: endpoint {
						remote-endpoint = <&corinth_etf_big_in>;
					};
				};
			};

			in-ports {
				#address-cells = <1>;
				#size-cells = <0>;

				port@0 {
					reg = <0>;
					funnel_core_in_port0: endpoint {
						remote-endpoint = <&etm0_out>;
					};
				};

				port@1 {
					reg = <1>;
					funnel_core_in_port1: endpoint {
						remote-endpoint = <&etm1_out>;
					};
				};

				port@2 {
					reg = <2>;
					funnel_core_in_port2: endpoint {
						remote-endpoint = <&etm2_out>;
					};
				};

				port@3 {
					reg = <3>;
					funnel_core_in_port6: endpoint {
						remote-endpoint = <&etm6_out>;
					};
				};
			};
		};

		etm0: etm@3f040000 {
			compatible = "arm,coresight-etm4x", "arm,primecell";
			reg = <0 0x3f040000 0 0x1000>;
			cpu = <&CPU0>;
			clocks = <&ext_26m>;
			clock-names = "apb_pclk";

			out-ports {
				port {
					etm0_out: endpoint {
						remote-endpoint =
						<&funnel_core_in_port0>;
					};
				};
			};
		};

		etm1: etm@3f140000 {
			compatible = "arm,coresight-etm4x", "arm,primecell";
			reg = <0 0x3f140000 0 0x1000>;
			cpu = <&CPU1>;
			clocks = <&ext_26m>;
			clock-names = "apb_pclk";

			out-ports {
				port {
					etm1_out: endpoint {
						remote-endpoint =
						<&funnel_core_in_port1>;
					};
				};
			};
		};

		etm2: etm@3f240000 {
			compatible = "arm,coresight-etm4x", "arm,primecell";
			reg = <0 0x3f240000 0 0x1000>;
			cpu = <&CPU2>;
			clocks = <&ext_26m>;
			clock-names = "apb_pclk";

			out-ports {
				port {
					etm2_out: endpoint {
						remote-endpoint =
						<&funnel_core_in_port2>;
					};
				};
			};
		};

		etm3: etm@3f340000 {
			compatible = "arm,coresight-etm4x", "arm,primecell";
			reg = <0 0x3f340000 0 0x1000>;
			cpu = <&CPU3>;
			clocks = <&ext_26m>;
			clock-names = "apb_pclk";

			out-ports {
				port {
					etm3_out: endpoint {
						remote-endpoint =
						<&funnel_core_in_port3>;
					};
				};
			};
		};

		etm4: etm@3f440000 {
			compatible = "arm,coresight-etm4x", "arm,primecell";
			reg = <0 0x3f440000 0 0x1000>;
			cpu = <&CPU4>;
			clocks = <&ext_26m>;
			clock-names = "apb_pclk";

			out-ports {
				port {
					etm4_out: endpoint {
						remote-endpoint =
						<&funnel_core_in_port4>;
					};
				};
			};
		};

		etm5: etm@3f540000 {
			compatible = "arm,coresight-etm4x", "arm,primecell";
			reg = <0 0x3f540000 0 0x1000>;
			cpu = <&CPU5>;
			clocks = <&ext_26m>;
			clock-names = "apb_pclk";

			out-ports {
				port {
					etm5_out: endpoint {
						remote-endpoint =
						<&funnel_core_in_port5>;
					};
				};
			};
		};

		etm6: etm@3f640000 {
			compatible = "arm,coresight-etm4x", "arm,primecell";
			reg = <0 0x3f640000 0 0x1000>;
			cpu = <&CPU6>;
			clocks = <&ext_26m>;
			clock-names = "apb_pclk";

			out-ports {
				port {
					etm6_out: endpoint {
						remote-endpoint =
						<&funnel_core_in_port6>;
					};
				};
			};
		};

		etm7: etm@3f740000 {
			compatible = "arm,coresight-etm4x", "arm,primecell";
			reg = <0 0x3f740000 0 0x1000>;
			cpu = <&CPU7>;
			clocks = <&ext_26m>;
			clock-names = "apb_pclk";

			out-ports {
				port {
					etm7_out: endpoint {
						remote-endpoint =
						<&funnel_core_in_port7>;
					};
				};
			};
		};

		apb@70000000 {
			compatible = "simple-bus";
			#address-cells = <1>;
			#size-cells = <1>;
			ranges = <0 0x0 0x70000000 0x10000000>;

			uart0: serial@0 {
				compatible = "sprd,ums512-uart",
					     "sprd,sc9836-uart";
				reg = <0x0 0x100>;
				interrupts = <GIC_SPI 2 IRQ_TYPE_LEVEL_HIGH>;
				clocks = <&ext_26m>;
				status = "disabled";
			};

			uart1: serial@100000 {
				compatible = "sprd,ums512-uart",
					     "sprd,sc9836-uart";
				reg = <0x100000 0x100>;
				interrupts = <GIC_SPI 3 IRQ_TYPE_LEVEL_HIGH>;
				clocks = <&ext_26m>;
				status = "disabled";
			};

			i2c0: i2c@300000 {
				compatible = "sprd,ums512-i2c", "sprd,sc9860-i2c";
				reg = <0x300000 0x100>;
				interrupts = <GIC_SPI 11 IRQ_TYPE_LEVEL_HIGH>;
				clock-frequency = <400000>;
				#address-cells = <1>;
				#size-cells = <0>;
				clock-names = "enable", "i2c", "source";
				clocks = <&apapb_gate CLK_I2C0_EB>,
					 <&ap_clk CLK_AP_I2C0>,
					 <&ext_26m>;
				status = "disabled";
			};

			i2c1: i2c@400000 {
				compatible = "sprd,ums512-i2c", "sprd,sc9860-i2c";
				reg = <0x400000 0x100>;
				interrupts = <GIC_SPI 12 IRQ_TYPE_LEVEL_HIGH>;
				clock-frequency = <400000>;
				#address-cells = <1>;
				#size-cells = <0>;
				clock-names = "enable", "i2c", "source";
				clocks = <&apapb_gate CLK_I2C1_EB>,
					 <&ap_clk CLK_AP_I2C1>,
					 <&ext_26m>;
				status = "disabled";
			};

			i2c2: i2c@500000 {
				compatible = "sprd,ums512-i2c", "sprd,sc9860-i2c";
				reg = <0x500000 0x100>;
				interrupts = <GIC_SPI 13 IRQ_TYPE_LEVEL_HIGH>;
				clock-frequency = <400000>;
				#address-cells = <1>;
				#size-cells = <0>;
				clock-names = "enable", "i2c", "source";
				clocks = <&apapb_gate CLK_I2C2_EB>,
					 <&ap_clk CLK_AP_I2C2>,
					 <&ext_26m>;
				status = "disabled";
			};

			i2c3: i2c@600000 {
				compatible = "sprd,ums512-i2c", "sprd,sc9860-i2c";
				reg = <0x600000 0x100>;
				interrupts = <GIC_SPI 14 IRQ_TYPE_LEVEL_HIGH>;
				clock-frequency = <400000>;
				#address-cells = <1>;
				#size-cells = <0>;
				clock-names = "enable", "i2c", "source";
				clocks = <&apapb_gate CLK_I2C3_EB>,
					 <&ap_clk CLK_AP_I2C3>,
					 <&ext_26m>;
				status = "disabled";
			};

			i2c4: i2c@700000 {
				compatible = "sprd,ums512-i2c", "sprd,sc9860-i2c";
				reg = <0x700000 0x100>;
				interrupts = <GIC_SPI 15 IRQ_TYPE_LEVEL_HIGH>;
				clock-frequency = <400000>;
				#address-cells = <1>;
				#size-cells = <0>;
				clock-names = "enable", "i2c", "source";
				clocks = <&apapb_gate CLK_I2C4_EB>,
					 <&ap_clk CLK_AP_I2C4>,
					 <&ext_26m>;
				status = "disabled";
			};

			sdio0: mmc@1100000 {
				compatible = "sprd,sdhci-r11";
				reg = <0x1100000 0x1000>;
				interrupts = <GIC_SPI 19 IRQ_TYPE_LEVEL_HIGH>;
				clocks = <&ap_clk CLK_SDIO0_2X>,
					 <&apapb_gate CLK_SDIO0_EB>;
				clock-names = "sdio", "enable";
				assigned-clocks = <&ap_clk CLK_SDIO0_2X>;
				assigned-clock-parents = <&pll1 CLK_RPLL>;
				status = "disabled";
			};

			sdio3: mmc@1400000 {
				compatible = "sprd,sdhci-r11";
				reg = <0x1400000 0x1000>;
				interrupts = <GIC_SPI 10 IRQ_TYPE_LEVEL_HIGH>;
				clocks = <&ap_clk CLK_EMMC_2X>,
					 <&apapb_gate CLK_EMMC_EB>;
				clock-names = "sdio", "enable";
				assigned-clocks = <&ap_clk CLK_EMMC_2X>;
				assigned-clock-parents = <&pll1 CLK_RPLL>;
				status = "disabled";
			};
		};

		aon: bus@32000000 {
			compatible = "simple-bus";
			#address-cells = <1>;
			#size-cells = <1>;
			ranges = <0 0x0 0x32000000 0x1000000>;

			adi_bus: spi@100000 {
				compatible = "sprd,ums512-adi";
				reg = <0x100000 0x100000>;
				#address-cells = <1>;
				#size-cells = <0>;
				sprd,hw-channels = <2 0x18cc>, <3 0x18cc>, <13 0x1854>, <15 0x1874>,
					<17 0x1844>,<19 0x1844>, <21 0x1864>, <30 0x1820>,
					<35 0x19b8>, <39 0x19ac>;
			};

			hwlock: hwspinlock@7f0000 {
				compatible = "sprd,hwspinlock-r3p0";
				reg = <0x7f0000 0x10000>;
				#hwlock-cells = <1>;
				clocks = <&aonapb_gate CLK_SPLK_EB>;
				clock-names = "enable";
			};

			ap_gpio: gpio@70000 {
				compatible = "sprd,ums512-gpio", "sprd,sc9860-gpio";
				reg = <0x70000 0x10000>;
				gpio-controller;
				#gpio-cells = <2>;
				interrupt-controller;
				#interrupt-cells = <2>;
				interrupts = <GIC_SPI 61 IRQ_TYPE_LEVEL_HIGH>;
			};

			pinctrl: pinctrl@450000 {
				compatible = "sprd,ums512-pinctrl";
				reg = <0x450000 0x3000>;

				/* VBC IIS interface muxing (stock values) */
				vbc_iis3_0: vbc-iis3-0 {
					pins = "UMS512_IIS_INF0_SYS_SEL";
					sprd,control = <0xe>;
				};

				vbc_iism0_0: vbc-iism0-0 {
					pins = "UMS512_IIS_INF0_SYS_SEL";
					sprd,control = <0xf>;
				};

				vbc_iis_to_pad: vbc-iis-to-pad {
					pins = "UMS512_VBC_IIS_INF_SYS_SEL";
					sprd,control = <0x0>;
				};

				vbc_iis_to_aon_usb: vbc-iis-to-aon-usb {
					pins = "UMS512_VBC_IIS_INF_SYS_SEL";
					sprd,control = <0x1>;
				};

				vbc_iism0_1: vbc-iism0-1 {
					pins = "UMS512_IIS_INF1_SYS_SEL";
					sprd,control = <0xf>;
				};

				vbc_iism0_3: vbc-iism0-3 {
					pins = "UMS512_IIS_INF3_SYS_SEL";
					sprd,control = <0xf>;
				};

				vbc_iis0_3: vbc-iis0-3 {
					pins = "UMS512_IIS_INF3_SYS_SEL";
					sprd,control = <0xb>;
				};

				vbc_iis1_3: vbc-iis1-3 {
					pins = "UMS512_IIS_INF3_SYS_SEL";
					sprd,control = <0xc>;
				};

				vbc_iis2_3: vbc-iis2-3 {
					pins = "UMS512_IIS_INF3_SYS_SEL";
					sprd,control = <0xd>;
				};

				vbc_iis3_3: vbc-iis3-3 {
					pins = "UMS512_IIS_INF3_SYS_SEL";
					sprd,control = <0xe>;
				};

				ap_iis0_3: ap-iis0-3 {
					pins = "UMS512_IIS_INF3_SYS_SEL";
					sprd,control = <0x0>;
				};
			};

			pwm: pwm@260000 {
				compatible = "sprd,ums512-pwm";
				reg = <0x260000 0x10000>;
				clocks = <&aon_clk CLK_PWM0>, <&aonapb_gate CLK_PWM0_EB>,
					 <&aon_clk CLK_PWM1>, <&aonapb_gate CLK_PWM1_EB>,
					 <&aon_clk CLK_PWM2>, <&aonapb_gate CLK_PWM2_EB>,
					 <&aon_clk CLK_PWM3>, <&aonapb_gate CLK_PWM3_EB>;
				clock-names = "pwm0", "enable0",
					      "pwm1", "enable1",
					      "pwm2", "enable2",
					      "pwm3", "enable3";
				assigned-clocks = <&aon_clk CLK_PWM0>,
						  <&aon_clk CLK_PWM1>,
						  <&aon_clk CLK_PWM2>,
						  <&aon_clk CLK_PWM3>;
				assigned-clock-parents = <&ext_26m>,
							 <&ext_26m>,
							 <&ext_26m>,
							 <&ext_26m>;
				#pwm-cells = <2>;
			};

			ap_thm0: thermal@200000 {
				compatible = "sprd,ums512-thermal";
				reg = <0x200000 0x10000>;
				#address-cells = <1>;
				#size-cells = <0>;
				clock-names = "enable";
				clocks = <&aonapb_gate CLK_THM0_EB>;
				#thermal-sensor-cells = <1>;
				nvmem-cells = <&thm0_sign>, <&thm0_ratio>;
				nvmem-cell-names = "thm_sign_cal", "thm_ratio_cal";

				sensor@0 {
					reg = <0>;
					nvmem-cells = <&thm0_sen0>;
					nvmem-cell-names = "sen_delta_cal";
				};

				sensor@1 {
					reg = <1>;
					nvmem-cells = <&thm0_sen1>;
					nvmem-cell-names = "sen_delta_cal";
				};

				sensor@2 {
					reg = <2>;
					nvmem-cells = <&thm0_sen2>;
					nvmem-cell-names = "sen_delta_cal";
				};

				sensor@3 {
					reg = <3>;
					nvmem-cells = <&thm0_sen3>;
					nvmem-cell-names = "sen_delta_cal";
				};

				sensor@4 {
					reg = <4>;
					nvmem-cells = <&thm0_sen4>;
					nvmem-cell-names = "sen_delta_cal";
				};
			};

			ap_thm1: thermal@210000 {
				compatible = "sprd,ums512-thermal";
				reg = <0x210000 0x10000>;
				#address-cells = <1>;
				#size-cells = <0>;
				clock-names = "enable";
				clocks = <&aonapb_gate CLK_THM1_EB>;
				#thermal-sensor-cells = <1>;
				nvmem-cells = <&thm1_sign>, <&thm1_ratio>;
				nvmem-cell-names = "thm_sign_cal", "thm_ratio_cal";

				sensor@0 {
					reg = <0>;
					nvmem-cells = <&thm1_sen0>;
					nvmem-cell-names = "sen_delta_cal";
				};

				sensor@1 {
					reg = <1>;
					nvmem-cells = <&thm1_sen1>;
					nvmem-cell-names = "sen_delta_cal";
				};

				sensor@2 {
					reg = <2>;
					nvmem-cells = <&thm1_sen2>;
					nvmem-cell-names = "sen_delta_cal";
				};

				sensor@3 {
					reg = <3>;
					nvmem-cells = <&thm1_sen3>;
					nvmem-cell-names = "sen_delta_cal";
				};

				sensor@4 {
					reg = <4>;
					nvmem-cells = <&thm1_sen4>;
					nvmem-cell-names = "sen_delta_cal";
				};

				sensor@5 {
					reg = <5>;
					nvmem-cells = <&thm1_sen5>;
					nvmem-cell-names = "sen_delta_cal";
				};
			};

			ap_thm2: thermal@220000 {
				compatible = "sprd,ums512-thermal";
				reg = <0x220000 0x10000>;
				#address-cells = <1>;
				#size-cells = <0>;
				clock-names = "enable";
				clocks = <&aonapb_gate CLK_THM2_EB>;
				#thermal-sensor-cells = <1>;
				nvmem-cells = <&thm2_sign>, <&thm2_ratio>;
				nvmem-cell-names = "thm_sign_cal", "thm_ratio_cal";

				sensor@0 {
					reg = <0>;
					nvmem-cells = <&thm2_sen0>;
					nvmem-cell-names = "sen_delta_cal";
				};
			};

			/*
			 * AP watchdog. Hardware only starts counting once userspace
			 * opens /dev/watchdogN (sprd_wdt_start(), not armed by the
			 * bootloader or on probe - confirmed in sprd_wdt.c), so this
			 * is a pure add: no risk of an unfed bootloader-armed timer
			 * biting before hw-watchdog.service starts feeding it.
			 * timeout-sec is set well above the service's 2s feed
			 * interval (6.16 used 12s) for margin against a stalled feed
			 * loop; SPRD_WDT_MAX_TIMEOUT is 60s.
			 */
			watchdog@2f0000 {
				compatible = "sprd,ums512-wdt", "sprd,sp9860-wdt";
				reg = <0x2f0000 0x10000>;
				interrupts = <GIC_SPI 79 IRQ_TYPE_LEVEL_HIGH>;
				timeout-sec = <30>;
				clock-names = "enable", "rtc_enable";
				clocks = <&aonapb_gate CLK_APCPU_WDG_EB>,
					 <&aonapb_gate CLK_AC_WDG_RTC_EB>;
			};
		};

		usb: usb@5fff0000 {
			compatible = "sprd,ums512-musb", "sprd,musb";
			reg = <0 0x5fff0000 0 0x2000>;
			interrupts = <GIC_SPI 69 IRQ_TYPE_LEVEL_HIGH>;
			interrupt-names = "mc";
			clocks = <&aonapb_gate CLK_OTG_UTMI_EB>;
			phys = <&hsphy>;
			status = "disabled";
		};

		thermal-zones {
			cputop0-thermal {
				polling-delay-passive = <100>;

				thermal-sensors = <&ap_thm0 0>;

				trips {
					cputop0_alert0: trip-point0 {
						temperature = <70000>;
						hysteresis = <1000>;
						type = "passive";
					};

					cputop0_critical: cpu-crit {
						temperature = <110000>;
						hysteresis = <2000>;
						type = "critical";
					};
				};

				cooling-maps {
					map0 {
						trip = <&cputop0_alert0>;
						/*
						 * cpufreq cooling registers one cooling device per
						 * policy on the policy's leading CPU (CPU0 = little
						 * cluster, cpu0-5 share a clock), so reference CPU0
						 * only; throttling it throttles the whole cluster.
						 */
						cooling-device = <&CPU0 THERMAL_NO_LIMIT THERMAL_NO_LIMIT>;
					};
				};
			};

			ank0-thermal {
				polling-delay-passive = <100>;

				thermal-sensors = <&ap_thm0 3>;

				trips {
					cpu0_alert0: trip-point0 {
						temperature = <70000>;
						hysteresis = <1000>;
						type = "passive";
					};

					cpu0_critical: cpu-crit {
						temperature = <110000>;
						hysteresis = <2000>;
						type = "critical";
					};
				};

				cooling-maps {
					map0 {
						trip = <&cpu0_alert0>;
						cooling-device = <&CPU0 THERMAL_NO_LIMIT THERMAL_NO_LIMIT>;
					};
				};
			};

			ank1-thermal {
				polling-delay-passive = <100>;

				thermal-sensors = <&ap_thm0 4>;

				trips {
					cpu1_alert0: trip-point0 {
						temperature = <70000>;
						hysteresis = <1000>;
						type = "passive";
					};

					cpu1_critical: cpu-crit {
						temperature = <110000>;
						hysteresis = <2000>;
						type = "critical";
					};
				};

				cooling-maps {
					map0 {
						trip = <&cpu1_alert0>;
						cooling-device = <&CPU0 THERMAL_NO_LIMIT THERMAL_NO_LIMIT>;
					};
				};
			};

			ank2-thermal {
				polling-delay-passive = <100>;

				thermal-sensors = <&ap_thm1 1>;

				trips {
					cpu2_alert0: trip-point0 {
						temperature = <70000>;
						hysteresis = <1000>;
						type = "passive";
					};

					cpu2_critical: cpu-crit {
						temperature = <110000>;
						hysteresis = <2000>;
						type = "critical";
					};
				};

				cooling-maps {
					map0 {
						trip = <&cpu2_alert0>;
						cooling-device = <&CPU0 THERMAL_NO_LIMIT THERMAL_NO_LIMIT>;
					};
				};
			};

			prometheus7-thermal {
				polling-delay-passive = <100>;

				thermal-sensors = <&ap_thm0 2>;

				trips {
					cpu7_alert0: trip-point0 {
						temperature = <70000>;
						hysteresis = <1000>;
						type = "passive";
					};

					cpu7_critical: cpu-crit {
						temperature = <110000>;
						hysteresis = <2000>;
						type = "critical";
					};
				};

				cooling-maps {
					map0 {
						trip = <&cpu7_alert0>;
						cooling-device = <&CPU6 THERMAL_NO_LIMIT THERMAL_NO_LIMIT>;
					};
				};
			};

			cputop1-thermal {
				polling-delay-passive = <100>;

				thermal-sensors = <&ap_thm0 1>;

				trips {
					cputop1_alert0: trip-point0 {
						temperature = <70000>;
						hysteresis = <1000>;
						type = "passive";
					};

					cputop1_critical: cpu-crit {
						temperature = <110000>;
						hysteresis = <2000>;
						type = "critical";
					};
				};

				cooling-maps {
					map0 {
						trip = <&cputop1_alert0>;
						/* CPU6 = big cluster leader (cpu6-7 share a clock). */
						cooling-device = <&CPU6 THERMAL_NO_LIMIT THERMAL_NO_LIMIT>;
					};
				};
			};

			gpu-thermal {
				polling-delay-passive = <100>;

				thermal-sensors = <&ap_thm1 0>;
			};

			gpuank2_thmzone: gpuank2-thmzone {
				polling-delay-passive = <0>;
				polling-delay = <0>;
				thermal-sensors = <&ap_thm2 0>;
			};

			ank3-thermal {
				polling-delay-passive = <100>;

				thermal-sensors = <&ap_thm1 2>;

				trips {
					cpu3_alert0: trip-point0 {
						temperature = <70000>;
						hysteresis = <1000>;
						type = "passive";
					};

					cpu3_critical: cpu-crit {
						temperature = <110000>;
						hysteresis = <2000>;
						type = "critical";
					};
				};

				cooling-maps {
					map0 {
						trip = <&cpu3_alert0>;
						cooling-device = <&CPU0 THERMAL_NO_LIMIT THERMAL_NO_LIMIT>;
					};
				};
			};

			ank4-thermal {
				polling-delay-passive = <100>;

				thermal-sensors = <&ap_thm1 3>;

				trips {
					cpu4_alert0: trip-point0 {
						temperature = <70000>;
						hysteresis = <1000>;
						type = "passive";
					};

					cpu4_critical: cpu-crit {
						temperature = <110000>;
						hysteresis = <2000>;
						type = "critical";
					};
				};

				cooling-maps {
					map0 {
						trip = <&cpu4_alert0>;
						cooling-device = <&CPU0 THERMAL_NO_LIMIT THERMAL_NO_LIMIT>;
					};
				};
			};

			ank5-thermal {
				polling-delay-passive = <100>;

				thermal-sensors = <&ap_thm1 4>;

				trips {
					cpu5_alert0: trip-point0 {
						temperature = <70000>;
						hysteresis = <1000>;
						type = "passive";
					};

					cpu5_critical: cpu-crit {
						temperature = <110000>;
						hysteresis = <2000>;
						type = "critical";
					};
				};

				cooling-maps {
					map0 {
						trip = <&cpu5_alert0>;
						cooling-device = <&CPU0 THERMAL_NO_LIMIT THERMAL_NO_LIMIT>;
					};
				};
			};

			prometheus6-thermal {
				polling-delay-passive = <100>;

				thermal-sensors = <&ap_thm1 5>;

				trips {
					cpu6_alert0: trip-point0 {
						temperature = <70000>;
						hysteresis = <1000>;
						type = "passive";
					};

					cpu6_critical: cpu-crit {
						temperature = <110000>;
						hysteresis = <2000>;
						type = "critical";
					};
				};

				cooling-maps {
					map0 {
						trip = <&cpu6_alert0>;
						cooling-device = <&CPU6 THERMAL_NO_LIMIT THERMAL_NO_LIMIT>;
					};
				};
			};
		};

		mm: mm {
			compatible = "simple-bus";
			#address-cells = <1>;
			#size-cells = <1>;
			ranges = <0x20300000 0x0 0x20300000 0x200000>;

			dpu: dpu@20300000 {
				compatible = "sprd,ums512-dpu", "sprd,sharkl3-dpu";
				reg = <0x20300000 0x800>;
				interrupts = <GIC_SPI 27 IRQ_TYPE_LEVEL_HIGH>;
				clocks = <&apahb_gate CLK_DISPC_EB>,
					 <&ap_clk CLK_DISPC0>,
					 <&ap_clk CLK_DISPC0_DPI>;
				clock-names = "core", "clk", "dpi";
				iommus = <&iommu_disp>;
				status = "disabled";

				dpu_port: port {
					dpu_out: endpoint {
						remote-endpoint = <&dsi_in>;
					};
				};
			};

			iommu_disp: iommu@20300800 {
				compatible = "sprd,ums512-iommu", "sprd,iommu-v1";
				reg = <0x20300800 0x80>;
				sprd,iova-range = <0x90000000 0x10000000>;
				#iommu-cells = <0>;
				status = "disabled";
			};

			dsi: dsi@20400000 {
				compatible = "sprd,ums512-dsi-host", "sprd,ums9230-dsi-host";
				reg = <0x20400000 0x1000>;
				interrupts = <GIC_SPI 30 IRQ_TYPE_LEVEL_HIGH>,
					     <GIC_SPI 31 IRQ_TYPE_LEVEL_HIGH>;
				clocks = <&apahb_gate CLK_DSI_EB>;
				clock-names = "pclk";

				/*
				 * MIPI DPHY analog block glue. Mirrors stock dphy
				 * node enable-syscon / power-syscon: driver sets
				 * phy-en bits to enable and clears phy-pwr bit to
				 * power up the analog driver.
				 */
				sprd,phy-en-syscon = <&ap_ahb_regs 0x40 0x03>;
				sprd,phy-pwr-syscon = <&ap_apb_regs 0x35c 0x08>;
				status = "disabled";

				ports {
					#address-cells = <1>;
					#size-cells = <0>;

					port@0 {
						reg = <0>;
						dsi_in: endpoint {
							remote-endpoint = <&dpu_out>;
						};
					};

					port@1 {
						reg = <1>;
						dsi_out: endpoint { };
					};
				};
			};
		};
	};

	ext_26m: clk-26m {
		compatible = "fixed-clock";
		#clock-cells = <0>;
		clock-frequency = <26000000>;
		clock-output-names = "ext-26m";
	};

	dphy_273m: dphy-273m {
		compatible = "fixed-clock";
		#clock-cells = <0>;
		clock-frequency = <273000000>;
		clock-output-names = "dphy-273m";
	};

	dphy_204m8: dphy-204m8 {
		compatible = "fixed-clock";
		#clock-cells = <0>;
		clock-frequency = <204800000>;
		clock-output-names = "dphy-204m8";
	};

	ext_32k: clk-32k {
		compatible = "fixed-clock";
		#clock-cells = <0>;
		clock-frequency = <32768>;
		clock-output-names = "ext-32k";
	};

	ext_4m: clk-4m {
		compatible = "fixed-clock";
		#clock-cells = <0>;
		clock-frequency = <4000000>;
		clock-output-names = "ext-4m";
	};

	rco_100m: clk-100m {
		compatible = "fixed-clock";
		#clock-cells = <0>;
		clock-frequency = <100000000>;
		clock-output-names = "rco-100m";
	};
};
